# A31G33x register map
Vendor: VENDOR ABOV Semiconductor Co., Ltd.; Series: A31G33x; File version: 1.0
CPU: CM0+ r0p1, little endian, no MPU, no FPU, VTOR, 2 interrupt priority bits
Registers are 32-bit, read-only, no defined reset value unless marked. A register's access mark holds for its fields unless they carry their own. Offsets are from the block's base; [hi:lo] are bit positions.

## RTCC — Real Time Clock and Calendar
Base 0x40005200
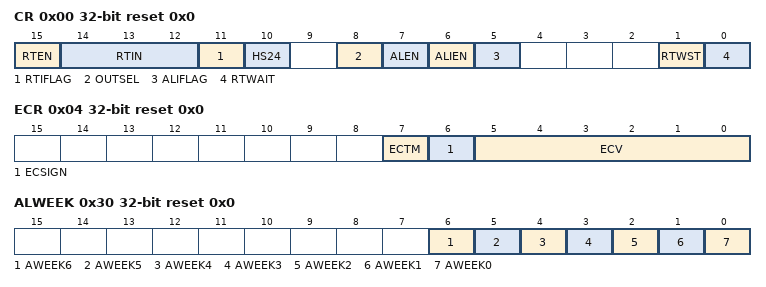
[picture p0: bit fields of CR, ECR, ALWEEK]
0x00 CR rw reset 0x0 — RTCC Control Register
  [15] RTEN — RTCC Enable
  [14:12] RTIN — RTCC Interrupt Interval Selection
  [11] RTIFLAG — RTCC Interval Interrupt Flag
  [10] HS24 — 12/24-hour System Selection
  [8] OUTSEL — RTCOUT Selection
  [7] ALEN — RTCC Alarm Match Operation Enable
  [6] ALIEN — RTCC Alarm Match Interrupt Enable
  [5] ALIFLAG — RTCC Alarm Match Interrupt Flag
  [1] RTWST ro — RTCC Wait Status Flag
  [0] RTWAIT — RTCC Wait Control
0x04 ECR rw reset 0x0 — RTCC Time Error Correcton Register
  [7] ECTM — Time Error Correction Timing Selection
  [6] ECSIGN — Time Error Correction Data Sign
  [5:0] ECV — Time Error Correction Data
0x08 SCNT reset 0x0 — RTCC Sub-counter Register
  [15:0] RTCNT — RTCC Sub-counter
0x0C SEC rw reset 0x0 — RTCC Second Counter Register
  [6:0] RSEC — RTCC Second Counter
0x10 MIN rw reset 0x0 — RTCC Minute Counter Register
  [6:0] RMIN — RTCC Minute Counter
0x14 HOUR rw reset 0x12 — RTCC Hour Counter Register
  [6:0] RHOUR — RTCC Hour Counter
0x18 DAY rw reset 0x1 — RTCC Day Counter Register
  [5:0] RDAY — RTCC Day Counter
0x1C WEEK rw reset 0x0 — RTCC Week Counter Register
  [2:0] RWEEK — RTCC Week Counter
0x20 MONTH rw reset 0x1 — RTCC Month Counter Register
  [4:0] RMONTH — RTCC Month Counter
0x24 YEAR rw reset 0x0 — RTCC Year Counter Register
  [7:0] RYEAR — RTCC Year Counter
0x28 ALMIN rw reset 0x0 — RTCC Alarm Minute Counter Register
  [6:0] AMIN — RTCC Alarm Minute Counter
0x2C ALHOUR rw reset 0x12 — RTCC Alarm Hour Counter Register
  [5:0] AHOUR — RTCC Alarm Hour Counter
0x30 ALWEEK rw reset 0x0 — RTCC Alarm Week Counter Register
  [6] AWEEK6 — Saturday Alarm Setting
  [5] AWEEK5 — Friday Alarm Setting
  [4] AWEEK4 — Thursday Alarm Setting
  [3] AWEEK3 — Wednesday Alarm Setting
  [2] AWEEK2 — Tuesday Alarm Setting
  [1] AWEEK1 — Monday Alarm Setting
  [0] AWEEK0 — Sunday Alarm Setting

## TIMER1n — Timer/Counter 1n
Base 0x53000000
Same registers: TIMER10 0x40002100, TIMER11 0x40002200, TIMER12 0x40002300, TIMER13 0x40002700, TIMER14 0x40002800, TIMER15 0x40002900
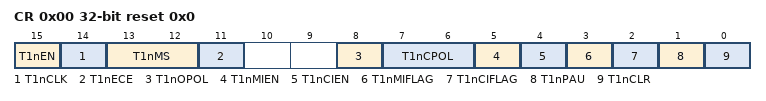
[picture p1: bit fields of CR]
0x00 CR rw reset 0x0 — TIMER1n Control Register
  [15] T1nEN — TIMER1n Operation Enable
  [14] T1nCLK — TIMER1n Clock Selection
  [13:12] T1nMS — TIMER1n Operation Mode Selection
  [11] T1nECE — TIMER1n External Clock Edge Selection
  [8] T1nOPOL — TIMER1n Output Polarity Selection
  [7:6] T1nCPOL — TIMER1n Capture Polarity Selection
  [5] T1nMIEN — TIMER1n Match Interrupt Enable
  [4] T1nCIEN — TIMER1n Capture Interrupt Enable
  [3] T1nMIFLAG — TIMER1n Match Interrupt Flag
  [2] T1nCIFLAG — TIMER1n Capture Interrupt Flag
  [1] T1nPAU — TIMER1n Counter Temporary Pause Control
  [0] T1nCLR — TIMER1n Counter and Prescaler Clear
0x04 ADR rw reset 0xFFFF — TIMER1n A Data Register
  [15:0] ADATA — TIMER1n A Data
0x08 BDR rw reset 0xFFFF — TIMER1n B Data Register
  [15:0] BDATA — TIMER1n B Data
0x0C CAPDR reset 0x0 — TIMER1n Capture Data Register
  [15:0] CAPD — TIMER1n Capture Data
0x10 PREDR rw reset 0xFFF — TIMER1n Prescaler Data Register
  [11:0] PRED — TIMER1n Prescaler Data
0x14 CNT reset 0x0 — TIMER1n Counter Register
  [15:0] CNT — TIMER1n Counter

## TIMER2n — Timer/Counter 2n
Base 0x54000000
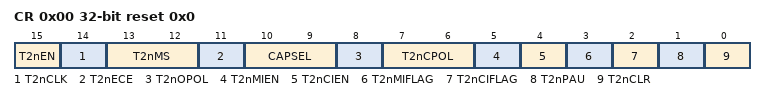
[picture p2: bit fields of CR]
0x00 CR rw reset 0x0 — TIMER2n Control Register
  [15] T2nEN — TIMER2n Operation Enable
  [14] T2nCLK — TIMER2n Clock Selection
  [13:12] T2nMS — TIMER2n Operation Mode Selection
  [11] T2nECE — TIMER2n External Clock Edge Selection
  [10:9] CAPSEL — TIMER2n Capture Signal Selection
  [8] T2nOPOL — TIMER2n Output Polarity Selection
  [7:6] T2nCPOL — TIMER2n Capture Polarity Selection
  [5] T2nMIEN — TIMER2n Match Interrupt Enable
  [4] T2nCIEN — TIMER2n Capture Interrupt Enable
  [3] T2nMIFLAG — TIMER2n Match Interrupt Flag
  [2] T2nCIFLAG — TIMER2n Capture Interrupt Flag
  [1] T2nPAU — TIMER2n Counter Temporary Pause Control
  [0] T2nCLR — TIMER2n Counter and Prescaler Clear
0x04 ADR rw reset 0xFFFFFFFF — TIMER2n A Data Register
  [31:0] ADATA — TIMER2n A Data
0x08 BDR rw reset 0xFFFFFFFF — TIMER2n B Data Register
  [31:0] BDATA — TIMER2n B Data
0x0C CAPDR reset 0x0 — TIMER2n Capture Data Register
  [31:0] CAPD — TIMER2n Capture Data
0x10 PREDR rw reset 0xFFF — TIMER2n Prescaler Data Register
  [11:0] PRED — TIMER2n Prescaler Data
0x14 CNT reset 0x0 — TIMER2n Counter Register
  [31:0] CNT — TIMER2n Counter
